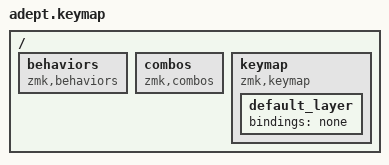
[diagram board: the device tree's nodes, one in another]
#include <input/processors.dtsi>
#include <dt-bindings/zmk/mouse.h>
#include <dt-bindings/zmk/behaviors.h>
#include <dt-bindings/zmk/input_transform.h>
#include <zephyr/dt-bindings/input/input-event-codes.h>
#include <behaviors.dtsi>
#include <dt-bindings/zmk/keys.h>
#include <dt-bindings/zmk/pointing.h>


/ {
    behaviors { compatible = "zmk,behaviors"; };

    combos { compatible = "zmk,combos"; };

    keymap {
        compatible = "zmk,keymap";
        default_layer {
            bindings = <&none>;
        };
    };
};
